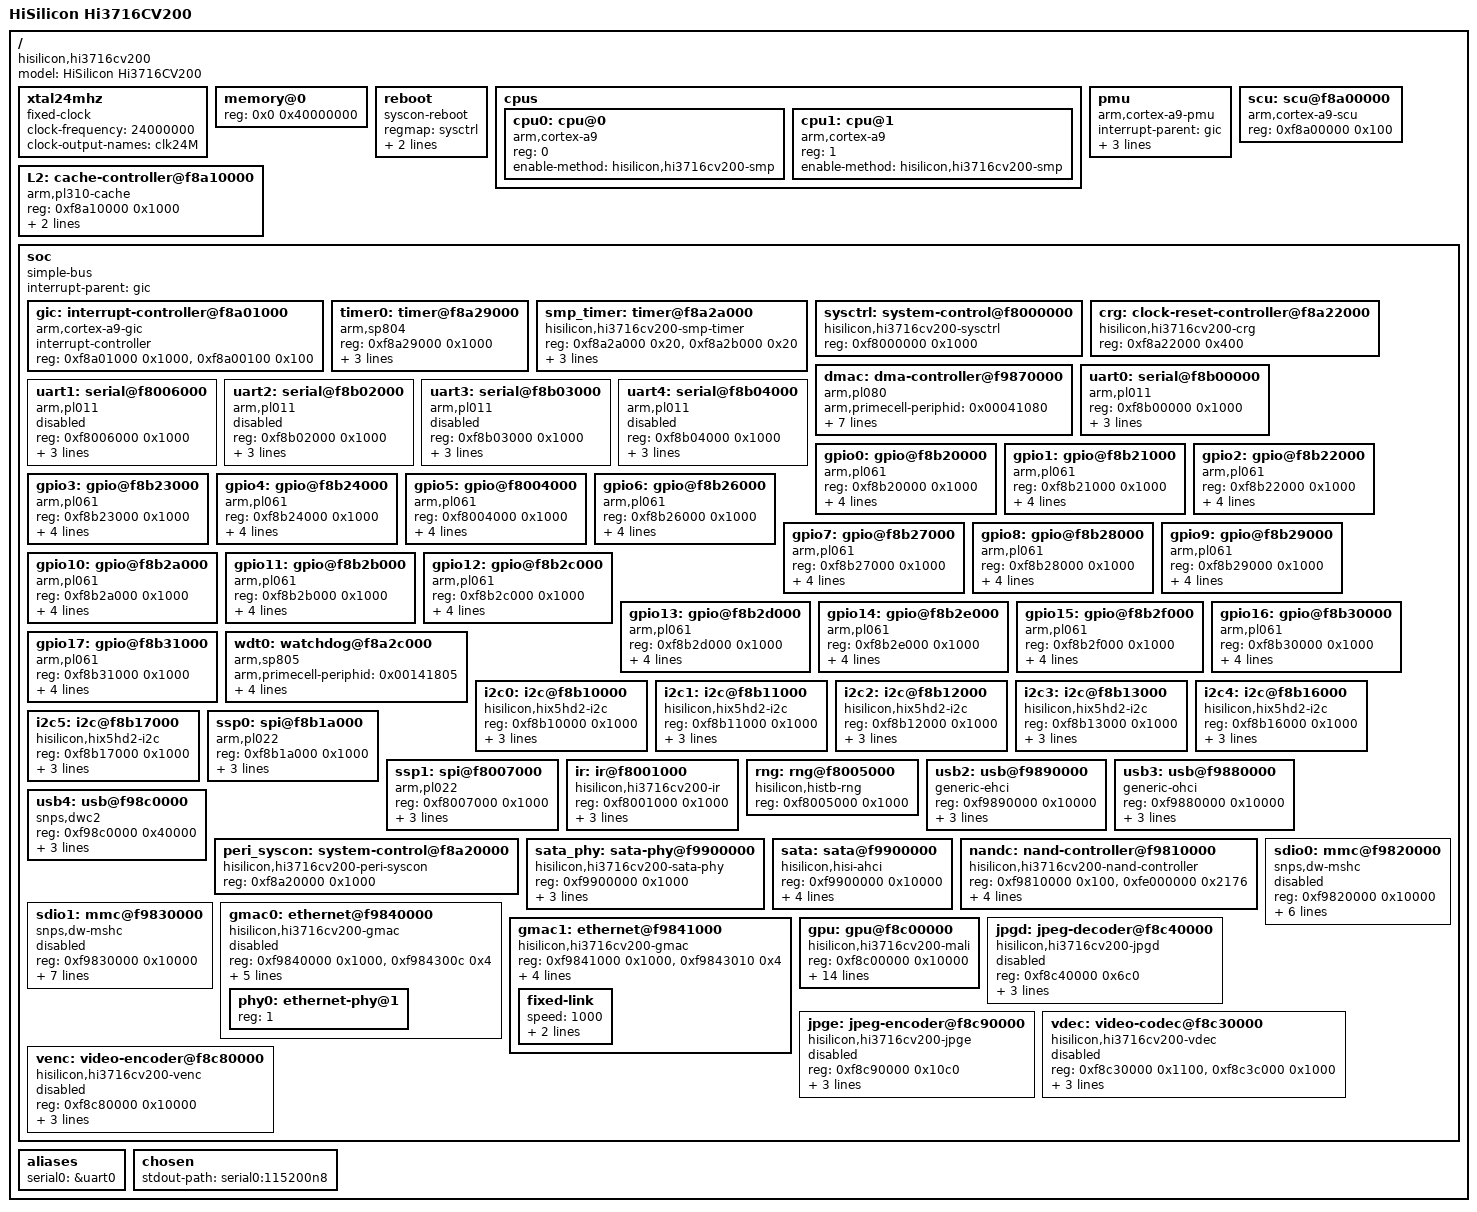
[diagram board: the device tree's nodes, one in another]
// SPDX-License-Identifier: GPL-2.0-or-later OR MIT
/*
 * HiSilicon Hi3716CV200 (2x Cortex-A9, 32-bit).
 *
 * Bring-up scaffolding for the AR513W board test: the node set is the one the
 * board itself proves, either from the 3.10 vendor board file
 * (kernel/linux-3.10.y/arch/arm/mach-s40/) or from the 4.4 vendor
 * arch/arm/boot/dts/hi3716cv200.dts. Gates and resets come from the CRG at
 * 0xf8a22000; the sources that have no documented PLL encoding are fixed clocks.
 */

#include <dt-bindings/clock/hisilicon,hi3716cv200-crg.h>
#include <dt-bindings/interrupt-controller/arm-gic.h>
#include <dt-bindings/interrupt-controller/irq.h>

/ {
	model = "HiSilicon Hi3716CV200";
	compatible = "hisilicon,hi3716cv200";
	#address-cells = <1>;
	#size-cells = <1>;

	xtal24mhz: xtal24mhz {
		compatible = "fixed-clock";
		#clock-cells = <0>;
		clock-frequency = <24000000>;
		clock-output-names = "clk24M";
	};

	/*
	 * The fixed sources (clk_3m, clk_83p3m, clk_i2c100m) are registered by
	 * the CRG provider, not here: a bit group reaches its source through a
	 * clk_hw owned by that provider, and a source declared in both places
	 * makes the second registration fail with -EEXIST, which aborts the CRG
	 * probe and leaves every clock, reset and bus consumer of it deferred.
	 */

	memory@0 {
		device_type = "memory";
		reg = <0x0 0x40000000>;
	};

	/*
	 * Not a child of the soc bus: every child of a simple-bus has to be
	 * addressable through its parent's ranges, and this node has no
	 * address of its own. The same shape is used at the top level by
	 * bcm7445.dtsi and rockchip/rk3288-veyron.dtsi.
	 */
	reboot {
		compatible = "syscon-reboot";
		regmap = <&sysctrl>;
		offset = <0x4>;
		mask = <0xdeadbeef>;
	};

	cpus {
		#address-cells = <1>;
		#size-cells = <0>;

		cpu0: cpu@0 {
			compatible = "arm,cortex-a9";
			device_type = "cpu";
			reg = <0>;
			enable-method = "hisilicon,hi3716cv200-smp";
		};

		cpu1: cpu@1 {
			compatible = "arm,cortex-a9";
			device_type = "cpu";
			reg = <1>;
			enable-method = "hisilicon,hi3716cv200-smp";
		};
	};

	/*
	 * The cores' performance monitor. There is no register to describe here:
	 * the counters live in the CPU bank the driver reaches through the cp15
	 * accessors, and what the device tree carries is where the overflow
	 * interrupt goes. The Cortex-A9 TRM puts it on private peripheral 6
	 * (GIC INTID 38); the sampling arm of boardtest/cv200-pmucheck.c is what
	 * says whether this SoC keeps that wiring, since the counters themselves
	 * run whether or not the interrupt is delivered.
	 */
	pmu {
		compatible = "arm,cortex-a9-pmu";
		/*
		 * The node sits at the root, where no interrupt-parent is inherited
		 * from: without this line the driver probes and reports
		 * "no irqs for PMU, sampling events not supported".
		 */
		interrupt-parent = <&gic>;
		interrupts = <GIC_PPI 6 IRQ_TYPE_LEVEL_HIGH>;
		interrupt-affinity = <&cpu0>, <&cpu1>;
		/*
		 * Inferred, and this property is the test of the inference: the
		 * board is booted by the vendor fastboot with no trusted-firmware
		 * layer, so the kernel is likely running in secure SVC. Measured
		 * 2026-10-22 with the interrupt wired: the armv7 driver announced
		 * 7 counters, /proc/interrupts listed arm-pmu, and yet the cycle
		 * and instruction counters both read 0 across a busy loop and the
		 * PMU interrupt count stayed 0. That is the signature of
		 * non-invasive debug being off -- PMCR/PMCNTENSET stay readable,
		 * the counters just do not tick -- and SDER.SUNIDEN is only
		 * reachable from secure state. If this boots, the state was
		 * secure; if the SDER access traps, it was not, and then the PMU
		 * cannot be enabled from this kernel at all.
		 */
		secure-reg-access;
	};

	/*
	 * The A9 MPCore private peripheral region: SCU at offset 0 of it, the GIC
	 * cpu interface at 0x100 (already described under the gic node). The vendor
	 * kernel reaches the same block through REG_BASE_A9_PERI 0xF8A00000
	 * (mach-s40/include/mach/platform.h:49).
	 */
	scu: scu@f8a00000 {
		compatible = "arm,cortex-a9-scu";
		reg = <0xf8a00000 0x100>;
	};

	/*
	 * The integrated L2C-310. Live reads (2026-10-25, bench devmem): CacheID
	 * 0x410000C9 (PL310 r3p2) at 0xf8a10000, CacheType 0x9e240240, and
	 * AuxCtrl 0x00000000 -- every boot the board has seen (vendor and ours)
	 * leaves the controller disabled; only its clock is up (CRG20 bit4
	 * l2_clkoff_sys = 0). No interrupt is described because the combi IRQ
	 * wiring is unknown and the l2x0 driver does not need one; the vendor
	 * kernels run with CONFIG_CACHE_L2X0 unset, so there is no vendor
	 * register word to copy the aux settings from and the driver's reset
	 * defaults apply.
	 */
	L2: cache-controller@f8a10000 {
		compatible = "arm,pl310-cache";
		reg = <0xf8a10000 0x1000>;
		cache-unified;
		cache-level = <2>;
	};

	soc {
		compatible = "simple-bus";
		interrupt-parent = <&gic>;
		#address-cells = <1>;
		#size-cells = <1>;
		ranges;

		gic: interrupt-controller@f8a01000 {
			compatible = "arm,cortex-a9-gic";
			#interrupt-cells = <3>;
			#address-cells = <0>;
			interrupt-controller;
			/* dist base, cpu interface base */
			reg = <0xf8a01000 0x1000>, <0xf8a00100 0x100>;
		};

		/*
		 * mach-s40/timer.c: cell 2 (0xf8a29000) is the clocksource,
		 * cell 3 (+0x20) the clockevent, both on the shared "timer2/3"
		 * line (SPI 25); cells 4 and 6 are the vendor's per-CPU local
		 * timers and are not used here -- the per-CPU event this kernel
		 * takes is the Cortex-A9 private timer below.
		 */
		timer0: timer@f8a29000 {
			/*
			 * "arm,sp804" only, deliberately: this instance answers its registers -- it is the
			 * running clocksource (current_clocksource = arm,sp804) -- but its PrimeCell ID
			 * header reads eight zero words at 0xfe0..0xffc, so listing "arm,primecell" made the
			 * bus core create a device with id 00000000 that nothing can ever match. That orphan
			 * was the whole of the "deferred probe pending" line this node used to print; the
			 * driver here is the OF timer path, which never goes through the AMBA bus.
			 */
			compatible = "arm,sp804";
			reg = <0xf8a29000 0x1000>;
			interrupts = <GIC_SPI 25 IRQ_TYPE_LEVEL_HIGH>;
			clocks = <&xtal24mhz>, <&xtal24mhz>, <&xtal24mhz>;
			clock-names = "apb_pclk", "timer0", "timer1";
			arm,sp804-has-irq = <2>;
		};

		/*
		 * Per-CPU clock events, one SP804 channel each: cell 4 for cpu0
		 * and cell 6 for cpu1, with their own SPIs -- the vendor picks a
		 * core's channel as hi_timer[(cpu * 2) + 4] and its build for this
		 * chip has HAVE_SP804_LOCAL_TIMER=y with HAVE_ARM_LOCAL_TIMER
		 * unset (mach-s40/timer.c:75, configs/hi3716cv200_defconfig:296).
		 * The Cortex-A9 private timer and global timer are unusable here:
		 * both keep the value written and never count (board-measured, and
		 * drivers/clocksource/timer-histb-smp.c has the numbers).
		 *
		 * The channel rate equals the clocksource cell's, 24 MHz, measured
		 * by counting both down over the same window, so the same fixed
		 * crystal describes them.
		 */
		smp_timer: timer@f8a2a000 {
			compatible = "hisilicon,hi3716cv200-smp-timer";
			reg = <0xf8a2a000 0x20>, <0xf8a2b000 0x20>;
			interrupts = <GIC_SPI 26 IRQ_TYPE_LEVEL_HIGH>,
				     <GIC_SPI 27 IRQ_TYPE_LEVEL_HIGH>;
			clocks = <&xtal24mhz>;
		};

		sysctrl: system-control@f8000000 {
			compatible = "hisilicon,hi3716cv200-sysctrl", "syscon";
			reg = <0xf8000000 0x1000>;
		};

		crg: clock-reset-controller@f8a22000 {
			compatible = "hisilicon,hi3716cv200-crg",
				"syscon", "simple-mfd";
			reg = <0xf8a22000 0x400>;
			#clock-cells = <1>;
			#reset-cells = <2>;
		};

		/*
		 * Same DMAC window, register set and request-line interrupt as
		 * the Hi3798MV100 instance (msp/drv/dmac/drv_dmac.h gives
		 * DMAC_BASE_REG 0xF9870000, DMAC_INT (30 + 32) and
		 * DMAC_CRG_BASE 0xF8A220A4 for this chip). dma-channels is
		 * carried over from the MV100 part and the PL08x driver honours
		 * it: channels 0..3 have to complete transfers here.
		 */
		dmac: dma-controller@f9870000 {
			compatible = "arm,pl080", "arm,primecell";
			/*
			 * The block reports 0x0a141080, which is bit for bit the ID
			 * the PL08x driver reserves for Samsung's PL080S variant:
			 * different channel configuration offset and 8-word list
			 * items, neither of which this has.  Declare the plain PL080
			 * ID, whose layout matches the register map here.
			 */
			arm,primecell-periphid = <0x00041080>;
			reg = <0xf9870000 0x10000>;
			interrupts = <GIC_SPI 30 IRQ_TYPE_LEVEL_HIGH>;
			clocks = <&crg HI3716CV200_DMAC_CLK>;
			clock-names = "apb_pclk";
			resets = <&crg 0xa4 4>;
			dma-channels = <4>;
			#dma-cells = <2>;
			memcpy-bus-width = <32>;
			memcpy-burst-size = <256>;
		};

		uart0: serial@f8b00000 {
			compatible = "arm,pl011", "arm,primecell";
			reg = <0xf8b00000 0x1000>;
			interrupts = <GIC_SPI 49 IRQ_TYPE_LEVEL_HIGH>;
			clocks = <&crg HI3716CV200_CLK_83P3M>,
				 <&crg HI3716CV200_CLK_83P3M>;
			clock-names = "uartclk", "apb_pclk";
		};

		/*
		 * The board's own /proc/iomem registers four more PL011 instances
		 * (`uart:1` 0xf8006000, `uart:2..4` 0xf8b02000/3000/4000), each a 4 KiB
		 * window, so these are the vendor's addresses rather than a stride guess.
		 * uart:1 sits in the SYS_CTRL window at 0xf8006000, not next to the others.
		 *
		 * Interrupt numbers come from mach/irqs.h's UART block (SPI 49..53); that
		 * header has been wrong for I2C, the SP804 timers and the MAC on this chip,
		 * but its UART0 entry is the one anchor the board confirms -- the console
		 * that works today is `GIC_SPI 49` and the vendor table counts it at ID 81.
		 * The remaining four are the contiguous rest of that block, and the board
		 * check that follows deliberately does not need them: PL011 requests the
		 * IRQ only when a port is opened, so the vendor's own /proc/interrupts
		 * lists just the console line and says nothing about the others.
		 */
		uart1: serial@f8006000 {
			compatible = "arm,pl011", "arm,primecell";
			reg = <0xf8006000 0x1000>;
			interrupts = <GIC_SPI 50 IRQ_TYPE_LEVEL_HIGH>;
			clocks = <&crg HI3716CV200_UART1_CLK>,
				 <&crg HI3716CV200_UART1_CLK>;
			clock-names = "uartclk", "apb_pclk";
			status = "disabled";
		};

		uart2: serial@f8b02000 {
			compatible = "arm,pl011", "arm,primecell";
			reg = <0xf8b02000 0x1000>;
			interrupts = <GIC_SPI 51 IRQ_TYPE_LEVEL_HIGH>;
			clocks = <&crg HI3716CV200_UART2_CLK>,
				 <&crg HI3716CV200_UART2_CLK>;
			clock-names = "uartclk", "apb_pclk";
			status = "disabled";
		};

		uart3: serial@f8b03000 {
			compatible = "arm,pl011", "arm,primecell";
			reg = <0xf8b03000 0x1000>;
			interrupts = <GIC_SPI 52 IRQ_TYPE_LEVEL_HIGH>;
			clocks = <&crg HI3716CV200_UART3_CLK>,
				 <&crg HI3716CV200_UART3_CLK>;
			clock-names = "uartclk", "apb_pclk";
			status = "disabled";
		};

		uart4: serial@f8b04000 {
			compatible = "arm,pl011", "arm,primecell";
			reg = <0xf8b04000 0x1000>;
			interrupts = <GIC_SPI 53 IRQ_TYPE_LEVEL_HIGH>;
			clocks = <&crg HI3716CV200_UART4_CLK>,
				 <&crg HI3716CV200_UART4_CLK>;
			clock-names = "uartclk", "apb_pclk";
			status = "disabled";
		};

		/*
		 * The GPIO banks are genuine ARM PL061 PrimeCells, so the in-tree
		 * driver is the whole port -- no new code. Measured on the production
		 * system of this board: the first bank's ID header reads PIDR0..3 =
		 * 0x61 0x10 0x04 0x00 and CIDR0..3 = 0x0d 0xf0 0x05 0xb1, i.e. the
		 * periphid 0x00041061 that is the only entry in gpio-pl061.c's amba_id
		 * table (mask 0x000fffff), and the register face the vendor GPIO HAL
		 * uses (boot/product/driver/gpio/drv_gpio.c g_GpioRegAddr, with
		 * DIR 0x400, IS 0x404, IBE 0x408, IEV 0x40c, IE 0x410, RIS 0x414,
		 * MIS 0x418, IC 0x41c -- msp/drv/include/hi_drv_gpio.h:193-200) is
		 * the PL061 map at the same offsets.
		 *
		 * 18 banks of 8 lines, and the production /proc/interrupts names eighteen GPIO rows:
		 * hi_gpio00_irq to hi_gpio17_irq at INTID 140 to 157, so every bank has its own wired
		 * interrupt. On this board those numbers are GIC INTIDs -- the same table gives 81 for
		 * uart-pl011, which is what this kernel measures for that device -- so bank n is
		 * SPI 108 + n, which is why the bank at 0xf8004000 sits between 0xf8b24000 and
		 * 0xf8b26000 and carries number five. An earlier capture read only the first nine rows
		 * and was taken for the bank count; the full table refutes that, and the nine banks it
		 * seemed to leave unparented are wired exactly like the first nine.
		 *
		 * What the production system leaves configured: every DIR reads
		 * 0x00000000 except 0xf8b24000 with bit 7 set and 0xf8b31000 with bit
		 * 4 set, i.e. two driven pins in the whole box. The always-on window's bank at
		 * 0xf8004000 is described like the rest: read under this kernel it answers
		 * PIDR0..3 = 61 10 04 00 (periphid 0x00041061, gpio-pl061.c's only id) and
		 * CIDR0..3 = 0d f0 05 b1, and the SDK names it REG_BASE_GPIO5 with
		 * MAX_GPIO_NUMS 18 (boot/fastboot/arch/arm/include/asm/arch-s40/platform.h).
		 * An earlier probe that seemed to get no answer was the probe's problem: the
		 * data window and the ID page both read fine.
		 */
		gpio0: gpio@f8b20000 {
			compatible = "arm,pl061", "arm,primecell";
			reg = <0xf8b20000 0x1000>;
			interrupts = <GIC_SPI 108 IRQ_TYPE_LEVEL_HIGH>;
			gpio-controller;
			#gpio-cells = <2>;
			interrupt-controller;
			#interrupt-cells = <2>;
			clocks = <&xtal24mhz>;
			clock-names = "apb_pclk";
		};

		gpio1: gpio@f8b21000 {
			compatible = "arm,pl061", "arm,primecell";
			reg = <0xf8b21000 0x1000>;
			interrupts = <GIC_SPI 109 IRQ_TYPE_LEVEL_HIGH>;
			gpio-controller;
			#gpio-cells = <2>;
			interrupt-controller;
			#interrupt-cells = <2>;
			clocks = <&xtal24mhz>;
			clock-names = "apb_pclk";
		};

		gpio2: gpio@f8b22000 {
			compatible = "arm,pl061", "arm,primecell";
			reg = <0xf8b22000 0x1000>;
			interrupts = <GIC_SPI 110 IRQ_TYPE_LEVEL_HIGH>;
			gpio-controller;
			#gpio-cells = <2>;
			interrupt-controller;
			#interrupt-cells = <2>;
			clocks = <&xtal24mhz>;
			clock-names = "apb_pclk";
		};

		gpio3: gpio@f8b23000 {
			compatible = "arm,pl061", "arm,primecell";
			reg = <0xf8b23000 0x1000>;
			interrupts = <GIC_SPI 111 IRQ_TYPE_LEVEL_HIGH>;
			gpio-controller;
			#gpio-cells = <2>;
			interrupt-controller;
			#interrupt-cells = <2>;
			clocks = <&xtal24mhz>;
			clock-names = "apb_pclk";
		};

		gpio4: gpio@f8b24000 {
			compatible = "arm,pl061", "arm,primecell";
			reg = <0xf8b24000 0x1000>;
			interrupts = <GIC_SPI 112 IRQ_TYPE_LEVEL_HIGH>;
			gpio-controller;
			#gpio-cells = <2>;
			interrupt-controller;
			#interrupt-cells = <2>;
			clocks = <&xtal24mhz>;
			clock-names = "apb_pclk";
		};

		gpio5: gpio@f8004000 {
			compatible = "arm,pl061", "arm,primecell";
			reg = <0xf8004000 0x1000>;
			interrupts = <GIC_SPI 113 IRQ_TYPE_LEVEL_HIGH>;
			gpio-controller;
			#gpio-cells = <2>;
			interrupt-controller;
			#interrupt-cells = <2>;
			clocks = <&xtal24mhz>;
			clock-names = "apb_pclk";
		};

		gpio6: gpio@f8b26000 {
			compatible = "arm,pl061", "arm,primecell";
			reg = <0xf8b26000 0x1000>;
			interrupts = <GIC_SPI 114 IRQ_TYPE_LEVEL_HIGH>;
			gpio-controller;
			#gpio-cells = <2>;
			interrupt-controller;
			#interrupt-cells = <2>;
			clocks = <&xtal24mhz>;
			clock-names = "apb_pclk";
		};

		gpio7: gpio@f8b27000 {
			compatible = "arm,pl061", "arm,primecell";
			reg = <0xf8b27000 0x1000>;
			interrupts = <GIC_SPI 115 IRQ_TYPE_LEVEL_HIGH>;
			gpio-controller;
			#gpio-cells = <2>;
			interrupt-controller;
			#interrupt-cells = <2>;
			clocks = <&xtal24mhz>;
			clock-names = "apb_pclk";
		};

		gpio8: gpio@f8b28000 {
			compatible = "arm,pl061", "arm,primecell";
			reg = <0xf8b28000 0x1000>;
			interrupts = <GIC_SPI 116 IRQ_TYPE_LEVEL_HIGH>;
			gpio-controller;
			#gpio-cells = <2>;
			interrupt-controller;
			#interrupt-cells = <2>;
			clocks = <&xtal24mhz>;
			clock-names = "apb_pclk";
		};

		/*
		 * Those nine banks carry their interrupts now, from the same table: INTID 149 to 157
		 * is SPI 117 to 125 in bank order. What the parentless experiment taught stays here,
		 * because it is why the driver change is right for any board that really does leave a
		 * bank unparented: gpio-pl061.c handed IRQ 0 to irq_set_chained_handler_and_data(),
		 * which warned once per such bank on every boot, so the driver now skips the whole
		 * irq side when adev->irq[0] is zero.
		 */
		gpio9: gpio@f8b29000 {
			compatible = "arm,pl061", "arm,primecell";
			reg = <0xf8b29000 0x1000>;
			interrupts = <GIC_SPI 117 IRQ_TYPE_LEVEL_HIGH>;
			gpio-controller;
			#gpio-cells = <2>;
			interrupt-controller;
			#interrupt-cells = <2>;
			clocks = <&xtal24mhz>;
			clock-names = "apb_pclk";
		};

		gpio10: gpio@f8b2a000 {
			compatible = "arm,pl061", "arm,primecell";
			reg = <0xf8b2a000 0x1000>;
			interrupts = <GIC_SPI 118 IRQ_TYPE_LEVEL_HIGH>;
			gpio-controller;
			#gpio-cells = <2>;
			interrupt-controller;
			#interrupt-cells = <2>;
			clocks = <&xtal24mhz>;
			clock-names = "apb_pclk";
		};

		gpio11: gpio@f8b2b000 {
			compatible = "arm,pl061", "arm,primecell";
			reg = <0xf8b2b000 0x1000>;
			interrupts = <GIC_SPI 119 IRQ_TYPE_LEVEL_HIGH>;
			gpio-controller;
			#gpio-cells = <2>;
			interrupt-controller;
			#interrupt-cells = <2>;
			clocks = <&xtal24mhz>;
			clock-names = "apb_pclk";
		};

		gpio12: gpio@f8b2c000 {
			compatible = "arm,pl061", "arm,primecell";
			reg = <0xf8b2c000 0x1000>;
			interrupts = <GIC_SPI 120 IRQ_TYPE_LEVEL_HIGH>;
			gpio-controller;
			#gpio-cells = <2>;
			interrupt-controller;
			#interrupt-cells = <2>;
			clocks = <&xtal24mhz>;
			clock-names = "apb_pclk";
		};

		gpio13: gpio@f8b2d000 {
			compatible = "arm,pl061", "arm,primecell";
			reg = <0xf8b2d000 0x1000>;
			interrupts = <GIC_SPI 121 IRQ_TYPE_LEVEL_HIGH>;
			gpio-controller;
			#gpio-cells = <2>;
			interrupt-controller;
			#interrupt-cells = <2>;
			clocks = <&xtal24mhz>;
			clock-names = "apb_pclk";
		};

		gpio14: gpio@f8b2e000 {
			compatible = "arm,pl061", "arm,primecell";
			reg = <0xf8b2e000 0x1000>;
			interrupts = <GIC_SPI 122 IRQ_TYPE_LEVEL_HIGH>;
			gpio-controller;
			#gpio-cells = <2>;
			interrupt-controller;
			#interrupt-cells = <2>;
			clocks = <&xtal24mhz>;
			clock-names = "apb_pclk";
		};

		gpio15: gpio@f8b2f000 {
			compatible = "arm,pl061", "arm,primecell";
			reg = <0xf8b2f000 0x1000>;
			interrupts = <GIC_SPI 123 IRQ_TYPE_LEVEL_HIGH>;
			gpio-controller;
			#gpio-cells = <2>;
			interrupt-controller;
			#interrupt-cells = <2>;
			clocks = <&xtal24mhz>;
			clock-names = "apb_pclk";
		};

		gpio16: gpio@f8b30000 {
			compatible = "arm,pl061", "arm,primecell";
			reg = <0xf8b30000 0x1000>;
			interrupts = <GIC_SPI 124 IRQ_TYPE_LEVEL_HIGH>;
			gpio-controller;
			#gpio-cells = <2>;
			interrupt-controller;
			#interrupt-cells = <2>;
			clocks = <&xtal24mhz>;
			clock-names = "apb_pclk";
		};

		gpio17: gpio@f8b31000 {
			compatible = "arm,pl061", "arm,primecell";
			reg = <0xf8b31000 0x1000>;
			interrupts = <GIC_SPI 125 IRQ_TYPE_LEVEL_HIGH>;
			gpio-controller;
			#gpio-cells = <2>;
			interrupt-controller;
			#interrupt-cells = <2>;
			clocks = <&xtal24mhz>;
			clock-names = "apb_pclk";
		};

		/*
		 * WDG0 and WDG1 are SP805 blocks; the vendor s40_restart() uses
		 * WDG0 the same way. PERI_CRG94 (0x178) gates them: bits 0..3
		 * are wdg0..3_cken, bits 4..7 the matching srst_req. Both bits of the pair
		 * belong to &crg's clk_wdt0 row: this driver consumes no reset control, so a
		 * `resets` cell here would leave the dog held in reset with nobody to release
		 * it, and a dog in reset does not count (see crg-hi3716cv200.c).
		 */
		wdt0: watchdog@f8a2c000 {
			compatible = "arm,sp805", "arm,primecell";
			/*
			 * This instance has no PrimeCell ID header: with the block
			 * clocked and out of reset (CRG94 0x0000000F) it answers at
			 * offset 0x00 but 0xfe0..0xffc read eight zero words, while a
			 * PL061 bank read in the same batch answers 61 10 04 00 /
			 * 05 b1 -- so the zeros are the hardware, not the read method.
			 * Nothing here is a measured ID: the property below presets
			 * adev->periphid (of/platform.c) and amba_device_add() then
			 * skips amba_read_periphid() entirely, so /sys .../id just
			 * echoes this constant. The value is the driver's own table
			 * entry (sp805_wdt_ids, mask 0x00ffffff), so bits 23:0 are
			 * all that carries meaning here.
			 */
			arm,primecell-periphid = <0x00141805>;
			reg = <0xf8a2c000 0x1000>;
			interrupts = <GIC_SPI 4 IRQ_TYPE_LEVEL_HIGH>;
			clocks = <&crg HI3716CV200_WDT0_CLK>, <&xtal24mhz>;
			clock-names = "wdog_clk", "apb_pclk";
			timeout-sec = <60>;
		};

		/*
		 * Same IP and same window as the mv100 adapters, so the upstream
		 * hix5hd2 bus driver drives them. Interrupt numbers are read off
		 * the board's own vendor Android /proc/interrupts (hi_i2c0..3 =
		 * 70..73), which the console uart (81 = GIC_SPI 49) cross-checks.
		 */
		i2c0: i2c@f8b10000 {
			compatible = "hisilicon,hix5hd2-i2c";
			reg = <0xf8b10000 0x1000>;
			interrupts = <GIC_SPI 38 IRQ_TYPE_LEVEL_HIGH>;
			clocks = <&crg HI3716CV200_I2C0_CLK>;
			clock-frequency = <400000>;
			#address-cells = <1>;
			#size-cells = <0>;
		};

		i2c1: i2c@f8b11000 {
			compatible = "hisilicon,hix5hd2-i2c";
			reg = <0xf8b11000 0x1000>;
			interrupts = <GIC_SPI 39 IRQ_TYPE_LEVEL_HIGH>;
			clocks = <&crg HI3716CV200_I2C1_CLK>;
			clock-frequency = <400000>;
			#address-cells = <1>;
			#size-cells = <0>;
		};

		i2c2: i2c@f8b12000 {
			compatible = "hisilicon,hix5hd2-i2c";
			reg = <0xf8b12000 0x1000>;
			interrupts = <GIC_SPI 40 IRQ_TYPE_LEVEL_HIGH>;
			clocks = <&crg HI3716CV200_I2C2_CLK>;
			clock-frequency = <400000>;
			#address-cells = <1>;
			#size-cells = <0>;
		};

		i2c3: i2c@f8b13000 {
			compatible = "hisilicon,hix5hd2-i2c";
			reg = <0xf8b13000 0x1000>;
			interrupts = <GIC_SPI 41 IRQ_TYPE_LEVEL_HIGH>;
			clocks = <&crg HI3716CV200_I2C3_CLK>;
			clock-frequency = <400000>;
			#address-cells = <1>;
			#size-cells = <0>;
		};

		/*
		 * The fifth adapter, which this chip's vendor header names I2C ADC:
		 * std_i2c/drv_i2c.h gives CHIP_TYPE_hi3716cv200 I2C4_PHY_ADDR 0xF8B16000
		 * with I2C4_IRQ (32 + 43), i.e. INTID 75 -- the same ID the vendor
		 * system's own /proc/interrupts row carries. CRG27 gates it with the
		 * bit 20/21 pair already modelled as HI3716CV200_I2C4_CLK. The QAM
		 * adapter at 0xF8B17000 (INTID 76) is marked "not used" in that header,
		 * so it stays out of the description until something on this board
		 * asks for it.
		 */
		i2c4: i2c@f8b16000 {
			compatible = "hisilicon,hix5hd2-i2c";
			reg = <0xf8b16000 0x1000>;
			interrupts = <GIC_SPI 43 IRQ_TYPE_LEVEL_HIGH>;
			clocks = <&crg HI3716CV200_I2C4_CLK>;
			clock-frequency = <400000>;
			#address-cells = <1>;
			#size-cells = <0>;
		};

		/*
		 * The sixth adapter this chip has and the production system registers: the SDK
		 * calls it QAMI2C (msp/drv/i2c/std_i2c/drv_i2c.h:104 gives 0xF8B17000, :113 the
		 * IRQ 32+44), and its /proc/interrupts row is hi_i2c5 at INTID 76, so SPI 44.
		 * Its clock gate is CRG27 bit 0 with the reset at bit 1 -- the family's sixth
		 * slot (drivers/clk/hisilicon/clk-hix5hd2.c:124) and the one pair the boot hands
		 * over held in reset along with the other five. Nothing is known to hang off
		 * this bus on this package, which is what the bench arm has to answer.
		 */
		i2c5: i2c@f8b17000 {
			compatible = "hisilicon,hix5hd2-i2c";
			reg = <0xf8b17000 0x1000>;
			interrupts = <GIC_SPI 44 IRQ_TYPE_LEVEL_HIGH>;
			clocks = <&crg HI3716CV200_I2C5_CLK>;
			clock-frequency = <400000>;
			#address-cells = <1>;
			#size-cells = <0>;
		};

		/*
		 * The two SSPs are Primecell PL022: the vendor register list is
		 * CR0/CR1/DR/SR/CPSR/IMSC/RIS/MIS/ICR plus the two FIFO thresholds at
		 * 0x28/0x2c (msp/drv/spi/drv_spi.c:67-89), and the bases are SPI0
		 * 0xf8b1a000 with SPI1 0xf8007000 for this chip -- the other branch of
		 * that #ifdef is the cv100/cv200_a pair at 0xf8b1b000 (drv_spi.c:51-60).
		 * The interrupts are the vendor's SPI0_IRQ (32+45) and SPI1_IRQ (32+46)
		 * (drv_spi.c:62-63), which are already GIC INTIDs, so they are SPI 45
		 * and 46 here.
		 *
		 * The same clock id feeds both names because CRG28 has one gate per
		 * port and no separate APB gate: sspclk is what the driver asks for and
		 * apb_pclk is the binding's second name for the same access.
		 */
		ssp0: spi@f8b1a000 {
			compatible = "arm,pl022", "arm,primecell";
			reg = <0xf8b1a000 0x1000>;
			interrupts = <GIC_SPI 45 IRQ_TYPE_LEVEL_HIGH>;
			clocks = <&crg HI3716CV200_SSP0_CLK>,
				 <&crg HI3716CV200_SSP0_CLK>;
			clock-names = "sspclk", "apb_pclk";
			#address-cells = <1>;
			#size-cells = <0>;
		};

		ssp1: spi@f8007000 {
			compatible = "arm,pl022", "arm,primecell";
			reg = <0xf8007000 0x1000>;
			interrupts = <GIC_SPI 46 IRQ_TYPE_LEVEL_HIGH>;
			clocks = <&crg HI3716CV200_SSP1_CLK>,
				 <&crg HI3716CV200_SSP1_CLK>;
			clock-names = "sspclk", "apb_pclk";
			#address-cells = <1>;
			#size-cells = <0>;
		};

		/*
		 * The IR receiver block is the same IP as the one the in-tree
		 * ir-hix5hd2 driver already drives: IR_IO_BASE 0xf8001000 with ENABLE
		 * 0x00, CONFIG 0x04, BUSY 0x1c, INTM 0x28, INTS 0x2c, INTC 0x30, START
		 * 0x34 (boot/product/driver/ir/ir.h:85 plus drv_ir_intf.c:43-57), and
		 * the value this board's own boot left in CONFIG -- 0x3e801f0b, read
		 * through /dev/mem -- puts 0x3e80 in the symbol-width field the driver
		 * writes. Its interrupt is ID 79 in the vendor /proc/interrupts
		 * (`hi_ir_std_irq`), i.e. GIC_SPI 47.
		 *
		 * The gate is *not* in the CRG: it is SYS_CTRL 0xf8000048 bit 4
		 * (enable) / bit 5 (reset), which is where the driver's hix5hd2_data
		 * clk_reg points and what this board reads as 0x00011111 (bit 4 set,
		 * bit 5 clear = running) before anything binds. No cv200 clock provider
		 * models that window yet, so the driver reaches it the way it was
		 * written for hix5hd2, through the syscon; `clocks` then only carries
		 * the 24 MHz reference the sample-time arithmetic divides by, and the
		 * vendor's own default freq index is 23 = 24 MHz - 1 (ir.h:90).
		 */
		ir: ir@f8001000 {
			compatible = "hisilicon,hi3716cv200-ir";
			reg = <0xf8001000 0x1000>;
			interrupts = <GIC_SPI 47 IRQ_TYPE_LEVEL_HIGH>;
			clocks = <&xtal24mhz>;
			hisilicon,power-syscon = <&sysctrl>;
		};

		/*
		 * The vendor cipher header names this window REG_RNG_BASE_ADDR and
		 * puts NUMBER at +4 and STAT at +8 (msp/drv/cipher/drv_cipher_reg.h:194),
		 * which is histb-rng's RNG_CTRL/RNG_NUMBER/RNG_STAT layout, so the in-tree
		 * driver is the whole port. It takes no clock: CRG49[0] sha_cken feeds this
		 * block and the CRG driver raises that gate itself.
		 */
		rng: rng@f8005000 {
			compatible = "hisilicon,histb-rng";
			reg = <0xf8005000 0x1000>;
		};

		/*
		 * USB2 host: two windows for one physical port set, which is how the
		 * generic host drivers expect it -- EHCI takes high-speed, OHCI the
		 * full/low-speed side. Both addresses are the vendor system's own
		 * claims (`hiusb-ehci.0` 0xf9890000, `hiusb-ohci.0` 0xf9880000 in its
		 * /proc/iomem, each one a 64 KiB window), and the interrupt IDs 98/99
		 * in its /proc/interrupts
		 * (`ehci_hcd:usb1`, `ohci_hcd:usb2`) are SPI 66/67 under the rule the
		 * console uart, aiao and the MAC already confirm here.
		 *
		 * The clock handles are what keep the probe honest rather than what
		 * turns the block on -- CRG46/CRG47 are raised by the clock provider
		 * itself -- but naming them means the host drivers cannot bind before
		 * the CRG has probed.
		 */
		usb2: usb@f9890000 {
			compatible = "generic-ehci";
			reg = <0xf9890000 0x10000>;
			interrupts = <GIC_SPI 66 IRQ_TYPE_LEVEL_HIGH>;
			clocks = <&crg HI3716CV200_USB_BUS_CLK>,
				 <&crg HI3716CV200_USB_PHY_CLK>;
		};

		usb3: usb@f9880000 {
			compatible = "generic-ohci";
			reg = <0xf9880000 0x10000>;
			interrupts = <GIC_SPI 67 IRQ_TYPE_LEVEL_HIGH>;
			clocks = <&crg HI3716CV200_USB_BUS_CLK>,
				 <&crg HI3716CV200_USB_PHY_CLK>;
		};

		/*
		 * The USB2 device controller. See the header of the commit that adds it for
		 * where each number comes from; what this node is *for* is to let dwc2 answer
		 * the one open question -- whether this block is a Synopsys DWC2 core -- with
		 * its own GSNPSID check instead of with the vendor driver's name.
		 */
		usb4: usb@f98c0000 {
			compatible = "snps,dwc2";
			reg = <0xf98c0000 0x40000>;
			interrupts = <GIC_SPI 68 IRQ_TYPE_LEVEL_HIGH>;
			clocks = <&crg HI3716CV200_USB_BUS_CLK>;
			clock-names = "otg";
			dr_mode = "peripheral";
		};

		/*
		 * The PERI block: the supply and hold bits for the on-chip
		 * peripherals, including the SATA disk supply the PHY driver
		 * switches. The internal DAC lives in the same window and keeps
		 * its own node.
		 */
		peri_syscon: system-control@f8a20000 {
			compatible = "hisilicon,hi3716cv200-peri-syscon",
				"syscon";
			reg = <0xf8a20000 0x1000>;
		};

		/*
		 * The SATA PHY shares the controller's window, and the block
		 * answers nothing until CRG42's bus and cko-alive reset bits
		 * have been pulsed -- measured on this board, where writing
		 * HOST_CTL.AHCI_EN with the clocks already at the vendor's 0x1F
		 * read back as zero until the pair was asserted and released.
		 */
		sata_phy: sata-phy@f9900000 {
			compatible = "hisilicon,hi3716cv200-sata-phy";
			reg = <0xf9900000 0x1000>;
			resets = <&crg 0xa8 8>, <&crg 0xa8 9>;
			#phy-cells = <0>;
			hisilicon,peri-syscon = <&peri_syscon>;
			hisilicon,power-reg = <0x8 10>;
		};

		/*
		 * SATA: the vendor system claims `ahci.0` at 0xf9900000 with a 64 KiB
		 * window and its `ahci` interrupt at ID 102, i.e. GIC_SPI 70. The
		 * in-tree ahci_platform driver carries the Hisi case by name, so the
		 * compatible is the one upstream already understands. Note the number
		 * trap: 70 here is an SPI *index* (INTID 102), while the I2C adapters
		 * above sit at INTIDs 70..73 -- different columns, no overlap.
		 */
		sata: sata@f9900000 {
			compatible = "hisilicon,hisi-ahci";
			reg = <0xf9900000 0x10000>;
			interrupts = <GIC_SPI 70 IRQ_TYPE_LEVEL_HIGH>;
			clocks = <&crg HI3716CV200_SATA_BUS_CLK>,
				 <&crg HI3716CV200_SATA_PHY_CLK>;
			phys = <&sata_phy>;
			phy-names = "sata-phy";
		};

		/*
		 * NAND: the hinfc610 block the box roots itself on. Two windows because
		 * the controller separates its register file from the byte window the
		 * command, address and status bytes travel through -- the vendor driver
		 * ioremaps the second one straight into the chip's IO_ADDR_R (the
		 * node's own `reg` pair in the vendor tree is the same two ranges).
		 * The ECC pair is what the running vendor system reports: CON reads
		 * 0x383 with ECCTYPE 1, which this block's table calls 8 bits per
		 * 1024-byte step, over a 2 KiB page.
		 */
		nandc: nand-controller@f9810000 {
			compatible = "hisilicon,hi3716cv200-nand-controller";
			reg = <0xf9810000 0x100>, <0xfe000000 0x2176>;
			clocks = <&crg HI3716CV200_NAND_CLK>;
			/* CRG24[4] nf_srst_req, the reset beside CRG24[0] nf_cken */
			resets = <&crg 0x60 4>;
			nand-ecc-strength = <8>;
			nand-ecc-step-size = <1024>;
			#address-cells = <1>;
			#size-cells = <0>;
		};

		/*
		 * The two DesignWare MSH hosts the vendor calls SDIO0 and SDIO1
		 * (drivers/mmc/host/himciv200/, CONFIG_HIMCIV200_SDIO{0,1}_IOBASE). Both
		 * windows decode: writing 0x200 then 0x2AA to BLKSIZ (0x1c) reads back two
		 * distinct values, and VERID (0x6c) says 0x5342250A on both -- measured on this
		 * board by boardtest/cv200-mdc.bench, image 26b3e02b265f4aeb14260ed0ad3141cc.
		 *
		 * **Correction, and it retracts what this comment said first: neither host has a
		 * card.** The CDETECT pair (MMC 1, SD 0) was read as "the package hangs off
		 * SDIO1"; the vendor system's own boot log on this very board says otherwise --
		 * `hi_mci1: eMMC/MMC/SD Device NOT detected!` with root on UBI over NAND
		 * (docs/ar513w-probe-2026-10-21/net/dmesg.txt). With the databook polarity that
		 * dw_mmc uses (card inserted pulls the line low, so it returns !(CDETECT & 1)),
		 * the MMC host's 1 means "absent" -- the driver was right and my reading of the
		 * word was wrong. The SD host's 0 is the one that would fake a card.
		 *
		 * Under dw_mmc the host itself is proven to the command level (image
		 * 074451469653677c3e56bc453fb0bf6f): CMD0 completes clean (`status=0x00000004`,
		 * CMD_DONE only) and every response-bearing command ends with
		 * `status=0x00000100` = CMD_DONE|RTO with all-zero response words, while
		 * pwren=1, clkdiv=0x3f (50 MHz / 2 / 63 = 396.8 kHz), clkena=0x00010001 and
		 * cmdr=0x2000c174-style words whose bit 31 START / bit 21 UPD_CLK / bit 15 INIT
		 * match the vendor's own encoding (himciv200_def.h:73-79). In other words the
		 * block is powered, clocked and issuing; the bus has nothing to answer. The
		 * interrupt is this driver's own line counting (INTID 67 -> GIC_SPI 35).
		 *
		 * So both hosts stay off on this board, and re-enabling one is a one-property
		 * change for a variant that actually fits an eMMC or a slot with a card.
		 *
		 * The interrupt cells are the two hi_mci lines the vendor system reports at
		 * INTID 66 and 67 (docs/ar513w-probe-2026-10-21/net/ints.txt) minus the SPI
		 * offset, and the 67 one is confirmed by this driver's own handler counting.
		 *
		 * HCON (0x70) reads 0x00E44C81: bits 17..16 are 0 there, which the driver
		 * maps to the block's own internal DMA manager, and the boot log confirms it
		 * ("IDMAC supports 32-bit address mode", "Using internal DMA controller").
		 * No external DMA is on this path, so the on-chip DMAC chain-transfer problem
		 * is not a dependency of the card.
		 *
		 * CRG39/CRG40 carry, next to the gate, the card-clock select (bits 8..9: 75,
		 * 100, 50, 24 MHz) and the sample/driver phase fields (himci_s40.c:4-68). The
		 * clock provider exposes one id per host covering both enable bits, so "biu" and
		 * "ciu" name the same cell -- which is also all the binding allows
		 * (synopsys-dw-mshc.yaml: clocks minItems/maxItems 2, names "biu" and "ciu").
		 * The card clock dw_mmc divides is the rate that id reports.
		 */
		sdio0: mmc@f9820000 {
			compatible = "snps,dw-mshc";
			reg = <0xf9820000 0x10000>;
			interrupts = <GIC_SPI 34 IRQ_TYPE_LEVEL_HIGH>;
			clocks = <&crg HI3716CV200_SDIO0_CLK>,
				 <&crg HI3716CV200_SDIO0_CLK>;
			clock-names = "biu", "ciu";
			bus-width = <4>;
			max-frequency = <50000000>;
			cap-sd-highspeed;
			status = "disabled";
		};

		sdio1: mmc@f9830000 {
			compatible = "snps,dw-mshc";
			reg = <0xf9830000 0x10000>;
			interrupts = <GIC_SPI 35 IRQ_TYPE_LEVEL_HIGH>;
			clocks = <&crg HI3716CV200_SDIO1_CLK>,
				 <&crg HI3716CV200_SDIO1_CLK>;
			clock-names = "biu", "ciu";
			bus-width = <8>;
			max-frequency = <50000000>;
			cap-mmc-highspeed;
			/*
			 * No non-removable here, and the earlier version of this node carried
			 * one on a false premise. dw_mci_get_cd() returns !(CDETECT & BIT(0))
			 * (dw_mmc.c:897), which is the databook polarity -- a pulled-high,
			 * unconnected detect reads "absent", exactly what the vendor's own boot
			 * log concludes for this board. Forcing the host to claim a card only
			 * made every rescan end in CMD_DONE|RTO, so the property described the
			 * missing detect pin, not a device.
			 */
			/*
			 * The rail word (0xf8a2011c) reads 0x60, the vendor's 3.3 V setting
			 * (himci_s40.c:181-191), and nothing here writes 0x20 for 1.8 V, so the
			 * host stays on 3.3 V signalling.
			 */
			no-1-8-v;
			/*
			 * Left disabled, and the reason is a measurement, not a guess. This was
			 * enabled on 2026-10-24 (with non-removable) on the premise that the
			 * production system's /proc/mtd names `block2mtd: /dev/block/mmcblk0p3`,
			 * i.e. that a partitioned MMC sits behind this window. That premise is
			 * contradicted by the vendor's own boot log on this very board:
			 * `hi_mci1: eMMC/MMC/SD Device NOT detected!`
			 * (docs/ar513w-probe-2026-10-21/net/dmesg.txt:208), with both hi_mci
			 * interrupt rows at 0 (net/ints.txt:6-7). Our round agreed: with the host
			 * enabled, every command on mmc1 returns CMD_DONE|RTO (-110) exactly like
			 * the empty SD slot, so nothing answers on the bus. The block2mtd line is
			 * therefore an artifact of that Android image's own init (its /proc/cmdline
			 * has no block2mtd=, so it was added at runtime, and it can only have come
			 * from the SD slot with a card present at the time).
			 *
			 * Keeping the host enabled would add a stream of command timeouts to
			 * every boot for no device. What would change this verdict is a card
			 * physically in the slot: the 2026-10-22 attempt reported one inserted and
			 * still saw only timeouts, and that half stays open.
			 */
			status = "disabled";
		};

		/*
		 * Port 1 of the gigabit switch fabric, the one wired to the Hi3620 side
		 * of this board (the vendor fastboot tftp path, and the vendor Linux
		 * eth1 with MAC ...1A:29). Same register map as the upstream
		 * hix5hd2_gmac driver: STATION_ADDR_LOW 0x0, MAC_DUPLEX_HALF_CTRL 0x8,
		 * PORT_MODE 0x40, PORT_EN 0x44, REC_FILT_CONTROL 0x64, RX_FQ_* 0x500+
		 * match boot/fastboot/drivers/net/higmacv300/ctrl.h one for one, so no
		 * new driver is needed. The interrupt is the gmac line the vendor
		 * system's own /proc/interrupts reports (103 for gmac0, 104 for gmac1:
		 * docs/ar513w-probe-2026-10-21/net/ints.txt), i.e. SPI 71/72. The
		 * s40 machine header mach-s40/include/mach/irqs.h is not usable as a
		 * table for this chip -- it puts INTNR_ETH at 32 + 51 = 83 and gives
		 * I2C2/I2C3 the same numbers as I2C0/I2C1.
		 */
		/*
		 * Port 0 is where the PHY actually hangs. Measured from my own kernel
		 * with the MDIO single-command registers: a read of address 1 register 2
		 * issued to 0xf98403c0 returns a value at 0xf98403c4 (0x0004 >> the
		 * 16-bit shift the controller applies), while the identical transaction
		 * on port 1 (0xf98413c0/0xf98413c4) reads back 0xFFFF. START (bit 20)
		 * self-clears on both, so neither bus is stuck -- one has a device on it
		 * and the other does not. PORT_MODE here reads 1 = PORT_MOD_100M_MII
		 * (higmacv300/higmac.h:60-65), what the bootloader left for this port.
		 */
		gmac0: ethernet@f9840000 {
			compatible = "hisilicon,hi3716cv200-gmac",
				     "hisilicon,hisi-gmac-v1";
			/*
			 * Left off for now: it probes and its MDIO has a device at
			 * address 1, but that device reads an all-zero ID and the port
			 * stays link-down, and this board's route to the Hi3620 is the
			 * other port. Kept in the file so the bus question can be picked
			 * up without rederiving the register map.
			 */
			status = "disabled";
			reg = <0xf9840000 0x1000>, <0xf984300c 0x4>;
			interrupts = <GIC_SPI 71 IRQ_TYPE_LEVEL_HIGH>;
			clocks = <&crg HI3716CV200_GMAC0_CLK>;
			clock-names = "mac_core";
			resets = <&crg 0xcc 10>;
			reset-names = "mac_ifc";
			phy-mode = "mii";
			phy-handle = <&phy0>;
			#address-cells = <1>;
			#size-cells = <0>;

			phy0: ethernet-phy@1 {
				reg = <1>;
			};
		};

		gmac1: ethernet@f9841000 {
			compatible = "hisilicon,hi3716cv200-gmac",
				     "hisilicon,hisi-gmac-v1";
			/*
			 * The MAC register block and the external interface control
			 * register the driver writes port speed/duplex into: for this
			 * port that word is HIGMAC_MACIF1_CTRL
			 * (boot/fastboot/drivers/net/higmacv300/ctrl.c:48 -- index 1
			 * writes MACIF1, ctrl.h:16 -- 0xF9843010).
			 */
			reg = <0xf9841000 0x1000>, <0xf9843010 0x4>;
			/*
			 * GIC interrupt ID 104. Taken from the vendor system's own
			 * /proc/interrupts on this board (docs/ar513w-probe-2026-10-21/
			 * raw.txt:153-159, where uart-pl011 is 81 -- the value my kernel
			 * measures for the same device -- so that table is in interrupt
			 * IDs, not Linux virtual numbers): gmac0 is 103, gmac1 is 104.
			 * mach-s40/include/mach/irqs.h:39's single INTNR_ETH = 32 + 51 is
			 * wrong the same way its I2C entries were.
			 */
			interrupts = <GIC_SPI 72 IRQ_TYPE_LEVEL_HIGH>;
			clocks = <&crg HI3716CV200_GMAC1_CLK>;
			clock-names = "mac_core";
			/*
			 * CRG51 bit 11 is gsf_mac1_srst_req, which the vendor pulses
			 * around every mac_if write (ctrl.c:22-37, `v |= 1 <<
			 * (ld->index + 10)` commented "bit10 mac_if0"), so it is the
			 * interface reset, not the core one; the port reset is bit 9
			 * (gsf_p1_srst_req) and stays unowned -- board-s40.c:37-89 does
			 * pulse bits 9 and 11 together (0x5 << (index + 8), hold 50 us)
			 * in higmac_restart(), but only after fwd_resume() has re-applied
			 * the fabric configuration, and measured on this board a reopen
			 * with that pair held went the wrong way: no frame was received at
			 * all afterwards and transmit stopped after 6 packets.
			 */
			resets = <&crg 0xcc 11>;
			reset-names = "mac_ifc";
			/*
			 * No source available here describes the delays on this
			 * PCB, so the port keeps plain rgmii: no tx or rx offset, no id.
			 */
			phy-mode = "rgmii";
			#address-cells = <1>;
			#size-cells = <0>;

			/*
			 * Measured: a single-command MDIO read of address 1 on this
			 * port's bus (0xf98413c0/0xf98413c4) returns nothing while the
			 * other port's bus has a device, yet the fastboot moves traffic
			 * here -- the peer is the Hi3620's own MAC, so the link is
			 * declared rather than negotiated.
			 */
			fixed-link {
				speed = <1000>;
				full-duplex;
				pause;
			};
		};

		/*
		 * Mali-400 MP4. The sub-block layout inside this one 64 KB window is
		 * what lima's mali400 column already describes (gp 0x0, l2_cache0 0x1000,
		 * pmu 0x2000, gpmmu 0x3000, ppmmu0..3 0x4000..0x7000, pp0..pp3
		 * 0x8000/0xa000/0xc000/0xe000 -- lima_device.c:52-66), and the vendor
		 * system's iomem table for this board lists the same ranges, so no
		 * per-SoC table entry is needed. Every interrupt source of the GPU is
		 * wired to a single GIC line -- the vendor's own /proc/interrupts has one
		 * row, "126: ... Mali_GP_MMU, Mali_GP, Mali_PP0_MMU, ..." -- so the same
		 * interrupt is named repeatedly; lima requests each of them with
		 * IRQF_SHARED, which makes that legal.
		 */
		gpu: gpu@f8c00000 {
			compatible = "hisilicon,hi3716cv200-mali", "arm,mali-400";
			reg = <0xf8c00000 0x10000>;
			interrupts = <GIC_SPI 94 IRQ_TYPE_LEVEL_HIGH>,
				     <GIC_SPI 94 IRQ_TYPE_LEVEL_HIGH>,
				     <GIC_SPI 94 IRQ_TYPE_LEVEL_HIGH>,
				     <GIC_SPI 94 IRQ_TYPE_LEVEL_HIGH>,
				     <GIC_SPI 94 IRQ_TYPE_LEVEL_HIGH>,
				     <GIC_SPI 94 IRQ_TYPE_LEVEL_HIGH>,
				     <GIC_SPI 94 IRQ_TYPE_LEVEL_HIGH>,
				     <GIC_SPI 94 IRQ_TYPE_LEVEL_HIGH>,
				     <GIC_SPI 94 IRQ_TYPE_LEVEL_HIGH>,
				     <GIC_SPI 94 IRQ_TYPE_LEVEL_HIGH>,
				     <GIC_SPI 94 IRQ_TYPE_LEVEL_HIGH>;
			interrupt-names = "gp", "gpmmu",
				"pp0", "ppmmu0", "pp1", "ppmmu1",
				"pp2", "ppmmu2", "pp3", "ppmmu3", "pmu";
			clocks = <&crg HI3716CV200_GPU_CLK>,
				 <&crg HI3716CV200_GPU_CLK>;
			clock-names = "bus", "core";
			resets = <&crg 0xd4 4>;
		};

		jpgd: jpeg-decoder@f8c40000 {
			compatible = "hisilicon,hi3716cv200-jpgd";
			reg = <0xf8c40000 0x6c0>;
			interrupts = <GIC_SPI 97 IRQ_TYPE_LEVEL_HIGH>;
			clocks = <&crg HI3716CV200_JPGD_CLK>;
			clock-names = "jpgd";
			resets = <&crg 0x7c 4>;
			reset-names = "jpgd";
			status = "disabled";
		};

		jpge: jpeg-encoder@f8c90000 {
			compatible = "hisilicon,hi3716cv200-jpge";
			reg = <0xf8c90000 0x10c0>;
			interrupts = <GIC_SPI 102 IRQ_TYPE_LEVEL_HIGH>;
			clocks = <&crg HI3716CV200_JPGE_CLK>;
			clock-names = "jpge";
			resets = <&crg 0x90 4>;
			reset-names = "jpge";
			status = "disabled";
		};

		/*
		 * The video decoder. Same block generation as the Hi3798MV100's as
		 * far as this kernel programs it: the vendor's firmware for this part
		 * puts the VDM at 0xf8c30000 and the SCD at 0xf8c3c000 and gives the
		 * doorbell interrupt as SPI 95 (vfmw_v4.0/firmware/product/
		 * Hi3716CV200/sysconfig.h:26,29,36 -- a file byte-identical to that
		 * part's). The VDM window is sized to reach the syntax-error record at
		 * 0x1014. HEVC is not in this part's codec list, unlike the
		 * Hi3798MV100's.
		 */
		vdec: video-codec@f8c30000 {
			compatible = "hisilicon,hi3716cv200-vdec";
			reg = <0xf8c30000 0x1100>, <0xf8c3c000 0x1000>;
			reg-names = "vdm", "scd";
			interrupts = <GIC_SPI 95 IRQ_TYPE_LEVEL_HIGH>;
			clocks = <&crg HI3716CV200_VDH_CLK>;
			clock-names = "vdec";
			resets = <&crg 0x78 4>, <&crg 0x78 6>;
			reset-names = "global", "vdm";
			status = "disabled";
		};

		/*
		 * The video encoder, present on silicon: read back at fastboot, the
		 * window answers and 0xf8c800fc gives 0x56325238, the revision string
		 * "V2R8" -- the r008 register file the vendor's own build selects for
		 * this part (msp/drv/venc/Makefile:26-29, hal_venc.h:11-12,27-30, which
		 * also gives the base here and SPI 101). No board config in the SDK
		 * enables it, so nothing has ever decoded through it.
		 */
		venc: video-encoder@f8c80000 {
			compatible = "hisilicon,hi3716cv200-venc";
			reg = <0xf8c80000 0x10000>;
			interrupts = <GIC_SPI 101 IRQ_TYPE_LEVEL_HIGH>;
			clocks = <&crg HI3716CV200_VENC_CLK>;
			clock-names = "venc";
			resets = <&crg 0x8c 4>;
			reset-names = "venc";
			status = "disabled";
		};
	};
};

/ {
	aliases {
		serial0 = &uart0;
	};

	chosen {
		stdout-path = "serial0:115200n8";
	};

};
